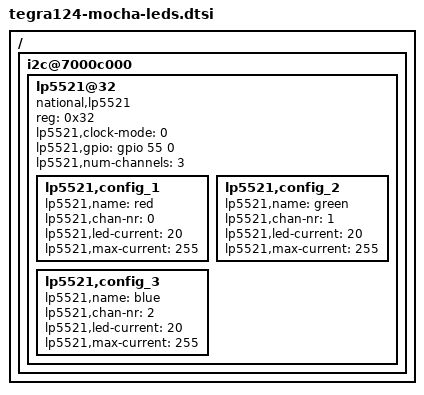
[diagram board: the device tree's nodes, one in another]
/ {
	i2c@7000c000 {
		lp5521@32 {
			compatible = "national,lp5521";
			reg = <0x32>;
			lp5521,clock-mode = <0>;
			lp5521,gpio = <&gpio 55 0>;
			lp5521,num-channels = <3>;

			lp5521,config_1 {
				lp5521,name = "red";
				lp5521,chan-nr = <0>;
				lp5521,led-current = <20>;
				lp5521,max-current = <255>;
			};
			lp5521,config_2 {
				lp5521,name = "green";
				lp5521,chan-nr = <1>;
				lp5521,led-current = <20>;
				lp5521,max-current = <255>;
			};
			lp5521,config_3 {
				lp5521,name = "blue";
				lp5521,chan-nr = <2>;
				lp5521,led-current = <20>;
				lp5521,max-current = <255>;
			};
		};
	};
};
